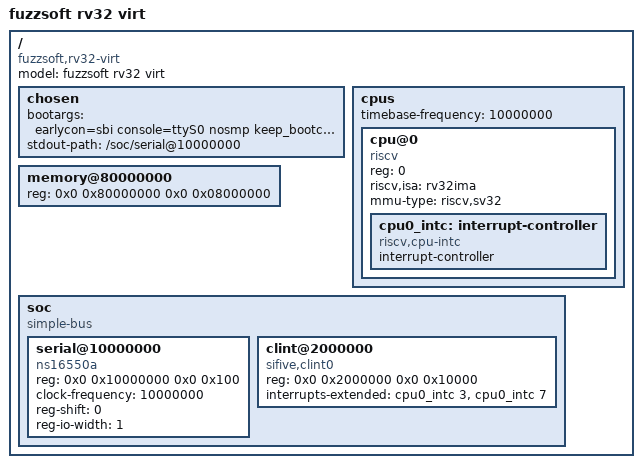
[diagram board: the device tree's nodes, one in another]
/dts-v1/;

/ {
	#address-cells = <2>;
	#size-cells = <2>;
	compatible = "fuzzsoft,rv32-virt";
	model = "fuzzsoft rv32 virt";

	chosen {
		bootargs = "earlycon=sbi console=ttyS0 nosmp keep_bootcon";
		stdout-path = "/soc/serial@10000000";
	};

	cpus {
		#address-cells = <1>;
		#size-cells = <0>;
		timebase-frequency = <10000000>;

		cpu@0 {
			device_type = "cpu";
			reg = <0>;
			status = "okay";
			compatible = "riscv";
			riscv,isa = "rv32ima";
			mmu-type = "riscv,sv32";

			cpu0_intc: interrupt-controller {
				#interrupt-cells = <1>;
				interrupt-controller;
				compatible = "riscv,cpu-intc";
			};
		};
	};

	memory@80000000 {
		device_type = "memory";
		reg = <0x0 0x80000000 0x0 0x08000000>; /* 128 MiB */
	};

	soc {
		#address-cells = <2>;
		#size-cells = <2>;
		compatible = "simple-bus";
		ranges;

		serial@10000000 {
			compatible = "ns16550a";
			reg = <0x0 0x10000000 0x0 0x100>;
			clock-frequency = <10000000>;
			reg-shift = <0>;
			reg-io-width = <1>;
		};

		clint@2000000 {
			compatible = "sifive,clint0", "riscv,clint0";
			reg = <0x0 0x2000000 0x0 0x10000>;
			interrupts-extended = <&cpu0_intc 3 &cpu0_intc 7>;
		};
	};
};
